# MIMXRT1042 register map
Vendor: nxp.com; File version: 1.0
CPU: CM7 r0p1, little endian, MPU, FPU, VTOR, 4 interrupt priority bits
Registers are 32-bit, read-write, reset 0x0 unless marked. A register's access mark holds for its fields unless they carry their own. Offsets are from the block's base; [hi:lo] are bit positions; {n}, {i} and the like mark numbered series.

## USDHC1 — uSDHC
Base 0x402C0000
Same registers: USDHC2 0x402C4000
0x00 DS_ADDR — DMA System Address
  [31:0] DS_ADDR — System address
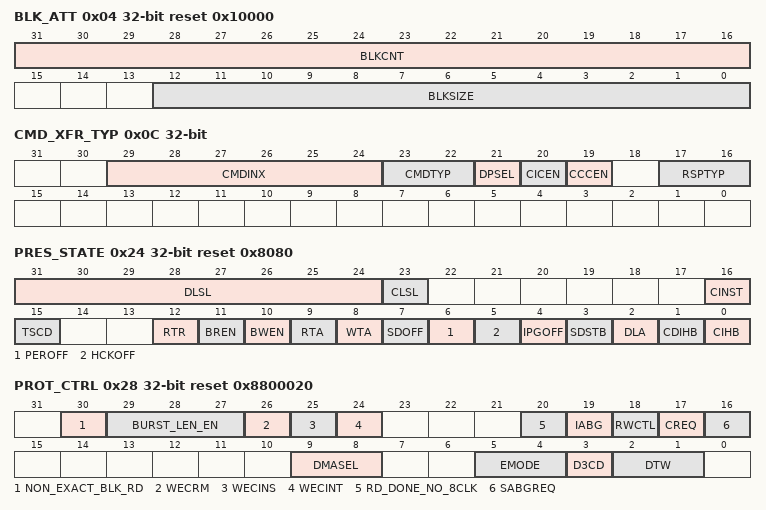
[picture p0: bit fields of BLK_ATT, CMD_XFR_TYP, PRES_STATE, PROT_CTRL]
0x04 BLK_ATT reset 0x10000 — Block Attributes
  [31:16] BLKCNT — Blocks count for current transfer
    0=BLKCNT_d (Stop count); 1=BLKCNT_c (1 block); 2=BLKCNT_b (2 blocks); 0xFFFF=BLKCNT_a (65535 blocks)
  [12:0] BLKSIZE — Transfer block size
    0=BLK_ATT_i (No data transfer); 1=BLK_ATT_h (1 byte); 2=BLK_ATT_g (2 bytes); 3=BLK_ATT_f (3 bytes); 4=BLK_ATT_e (4 bytes); 0x1FF=BLK_ATT_d (511 bytes); 0x200=BLK_ATT_c (512 bytes); 0x800=BLK_ATT_b (2048 bytes); 0x1000=BLK_ATT_a (4096 bytes)
0x08 CMD_ARG — Command Argument
  [31:0] CMDARG — Command argument
0x0C CMD_XFR_TYP — Command Transfer Type
  [29:24] CMDINX — Command index
  [23:22] CMDTYP — Command type
    0=CMDTYP_d (Normal other commands); 1=CMDTYP_c (Suspend CMD52 for writing bus suspend in CCCR); 2=CMDTYP_b (Resume CMD52 for writing function select in CCCR); 3=CMDTYP_a (Abort CMD12, CMD52 for writing I/O Abort in CCCR)
  [21] DPSEL — Data present select
    0=DPSEL_b (No data present); 1=DPSEL_a (Data present)
  [20] CICEN — Command index check enable
    0=CICEN_b (Disable command index check); 1=CICEN_a (Enables command index check)
  [19] CCCEN — Command CRC check enable
    0=CCCEN_b (Disables command CRC check); 1=CCCEN_a (Enables command CRC check)
  [17:16] RSPTYP — Response type select
    0=RSPTYP_a (No response); 1=RSPTYP_b (Response length 136); 2=RSPTYP_c (Response length 48); 3=RSPTYP_d (Response length 48, check busy after response)
{0x10+4i} CMD_RSP{i} ro (i=0..3) — Command Response{i}
  [31:0] CMDRSP{i} — Command response {i}
0x20 DATA_BUFF_ACC_PORT — Data Buffer Access Port
  [31:0] DATCONT — Data content
0x24 PRES_STATE ro reset 0x8080 (reset mask 0x7EFFFF) — Present State
  [31:24] DLSL — DATA[7:0] line signal level
    {v}=DATA{v} (Data {v} line signal level) (v=0..7)
  [23] CLSL — CMD line signal level
  [16] CINST — Card inserted
    0=CINST_a (Power on reset or no card); 1=CINST_B (Card inserted)
  [15] TSCD — Tap select change done
    0=TSCD_B (Delay cell select change is not finished.); 1=TSCD_A (Delay cell select change is finished.)
  [12] RTR — Re-Tuning Request (only for SD3.0 SDR104 mode,and eMMC HS200 mode)
    0=RTR_B (Fixed or well tuned sampling clock); 1=RTR_A (Sampling clock needs re-tuning)
  [11] BREN — Buffer read enable
    0=BREN_B (Read disable); 1=BREN_A (Read enable)
  [10] BWEN — Buffer write enable
    0=BWEN_b (Write disable); 1=BWEN_A (Write enable)
  [9] RTA — Read transfer active
    0=RTA_B (No valid data); 1=RTA_A (Transferring data)
  [8] WTA — Write transfer active
    0=WTA_B (No valid data); 1=WTA_A (Transferring data)
  [7] SDOFF — SD clock gated off internally
    0=SDOFF_D (SD clock is active.); 1=SDOFF_C (SD clock is gated off.)
  [6] PEROFF — IPG_PERCLK gated off internally
    0=PEROFF_b (IPG_PERCLK is active.); 1=PEROFF_A (IPG_PERCLK is gated off.)
  [5] HCKOFF — HCLK gated off internally
    0=HCKOFF_B (HCLK is active.); 1=HCKOFF_A (HCLK is gated off.)
  [4] IPGOFF — Peripheral clock gated off internally
    0=IPGOFF_b (Peripheral clock is active.); 1=IPGOFF_A (Peripheral clock is gated off.)
  [3] SDSTB — SD clock stable
    0=SDSTB_b (Clock is changing frequency and not stable.); 1=SDSTB_A (Clock is stable.)
  [2] DLA — Data line active
    0=DLA_A (DATA line inactive); 1=DLA_b (DATA line active)
  [1] CDIHB — Command Inhibit Data (DATA)
    0=CDIHB_b (Can issue command that uses the DATA line); 1=CDIHB_A (Cannot issue command that uses the DATA line)
  [0] CIHB — Command inhibit (CMD)
    0=CIHB_a (Can issue command using only CMD line); 1=CIHB_b (Cannot issue command)
0x28 PROT_CTRL reset 0x8800020 — Protocol Control
  [30] NON_EXACT_BLK_RD — Non-exact block read
    0=EXACT_B (The block read is exact block read. Host driver does not need to issue abort command to terminate this multi-block read.); 1=EXACT_A (The block read is non-exact block read. Host driver needs to issue abort command to terminate this multi-block read.)
  [29:27] BURST_LEN_EN — BURST length enable for INCR, INCR4 / INCR8 / INCR16, INCR4-WRAP / INCR8-WRAP / INCR16-WRAP
    0bxx1=BURST_A (Burst length is enabled for INCR.)
  [26] WECRM — Wakeup event enable on SD card removal
    0=WECRM_B (Disables wakeup event enable on SD card removal); 1=WECRM_A (Enables wakeup event enable on SD card removal)
  [25] WECINS — Wakeup event enable on SD card insertion
    0=WECINS_b (Disable wakeup event enable on SD card insertion); 1=WECINS_A (Enable wakeup event enable on SD card insertion)
  [24] WECINT — Wakeup event enable on card interrupt
    0=WECINT_A (Disables wakeup event enable on card interrupt); 1=WECINT_b (Enables wakeup event enable on card interrupt)
  [20] RD_DONE_NO_8CLK — Read performed number 8 clock
  [19] IABG — Interrupt at block gap
    0=IABG_b (Disables interrupt at block gap); 1=IABG_A (Enables interrupt at block gap)
  [18] RWCTL — Read wait control
    0=RWCTL_b (Disables read wait control and stop SD clock at block gap when SABGREQ field is set); 1=RWCTL_A (Enables read wait control and assert read wait without stopping SD clock at block gap when SABGREQ field is set)
  [17] CREQ — Continue request
    0=CREQ_B (No effect); 1=CREQ_A (Restart)
  [16] SABGREQ — Stop at block gap request
    0=SABGREQ_b (Transfer); 1=SABGREQ_A (Stop)
  [9:8] DMASEL — DMA select
    0=DMASEL_A (No DMA or simple DMA is selected.); 1=DMASEL_b (ADMA1 is selected.); 2=DMASEL_C (ADMA2 is selected.)
  [5:4] EMODE — Endian mode
    0=EMODE_A (Big endian mode); 1=EMODE_B (Half word big endian mode); 2=EMODE_C (Little endian mode)
  [3] D3CD — DATA3 as card detection pin
    0=D3CD_B (DATA3 does not monitor card insertion); 1=D3CD_A (DATA3 as card detection pin)
  [2:1] DTW — Data transfer width
    0=DTW_C (1-bit mode); 1=DTW_B (4-bit mode); 2=DTW_A (8-bit mode)
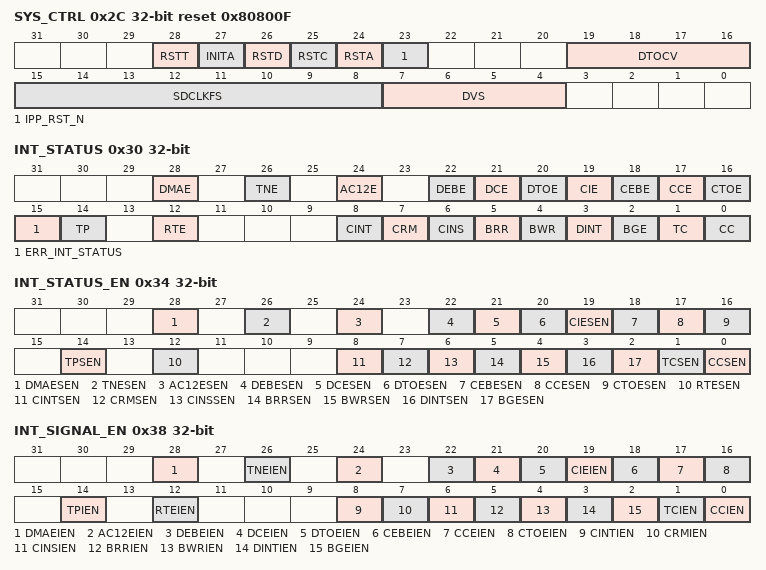
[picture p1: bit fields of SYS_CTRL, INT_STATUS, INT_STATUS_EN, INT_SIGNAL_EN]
0x2C SYS_CTRL reset 0x80800F — System Control
  [28] RSTT — Reset tuning
  [27] INITA — Initialization active
  [26] RSTD — Software reset for data line
    0=RSTD_B (No reset); 1=RSTD_A (Reset)
  [25] RSTC — Software reset for CMD line
    0=RSTC_B (No reset); 1=RSTC_A (Reset)
  [24] RSTA — Software reset for all
    0=RSTA_B (No reset); 1=RSTA_A (Reset)
  [23] IPP_RST_N — Hardware reset
  [19:16] DTOCV — Data timeout counter value
    0=DTOCV_Q (SDCLK x 2 14); 1=DTOCV_P (SDCLK x 2 15); 2=DTOCV_O (SDCLK x 2 16); 3=DTOCV_N (SDCLK x 2 17); 4=DTOCV_M (SDCLK x 2 18); 5=DTOCV_L (SDCLK x 2 19); 6=DTOCV_K (SDCLK x 2 20); 7=DTOCV_J (SDCLK x 2 21); 8=DTOCV_I (SDCLK x 2 22); 9=DTOCV_H (SDCLK x 2 23); 10=DTOCV_G (SDCLK x 2 24); 11=DTOCV_F (SDCLK x 2 25); 12=DTOCV_E (SDCLK x 2 26); 13=DTOCV_D (SDCLK x 2 27); 14=DTOCV_C (SDCLK x 2 28); 15=DTOCV_A (SDCLK x 2 29)
  [15:8] SDCLKFS — SDCLK frequency select
  [7:4] DVS — Divisor
    0=DVS_A (Divide-by-1); 1=DVS_B (Divide-by-2); 14=DVS_C (Divide-by-15); 15=DVS_D (Divide-by-16)
0x30 INT_STATUS — Interrupt Status
  [28] DMAE write-1-clears — DMA error
    0=DMAE_A (No error); 1=DMAE_b (Error)
  [26] TNE write-1-clears — Tuning error: (only for SD3.0 SDR104 mode and eMMC HS200 mode)
  [24] AC12E write-1-clears — Auto CMD12 error
    0=AC12E_A (No error); 1=AC12E_b (Error)
  [22] DEBE write-1-clears — Data end bit error
    0=DEBE_A (No error); 1=DEBE_b (Error)
  [21] DCE write-1-clears — Data CRC error
    0=DCE_A (No error); 1=DCE_b (Error)
  [20] DTOE write-1-clears — Data timeout error
    0=DTOE_A (No error); 1=DTOE_b (Time out)
  [19] CIE write-1-clears — Command index error
    0=CIE_A (No error); 1=CIE_b (Error)
  [18] CEBE write-1-clears — Command end bit error
    0=CEBE_A (No error); 1=CEBE_b (End bit error generated)
  [17] CCE write-1-clears — Command CRC error
    0=CCE_A (No error); 1=CCE_b (CRC error generated)
  [16] CTOE write-1-clears — Command timeout error
    0=CTOE_A (No error); 1=CTOE_b (Time out)
  [15] ERR_INT_STATUS ro — Error Interrupt Status
  [14] TP write-1-clears — Tuning pass:(only for SD3.0 SDR104 mode and eMMC HS200 mode)
  [12] RTE write-1-clears — Re-tuning event: (only for SD3.0 SDR104 mode and eMMC HS200 mode)
    0=RTE_A (Re-tuning is not required.); 1=RTE_b (Re-tuning should be performed.)
  [8] CINT write-1-clears — Card interrupt
    0=CINT_A (No card interrupt); 1=CINT_b (Generate card interrupt)
  [7] CRM write-1-clears — Card removal
    0=CRM_A (Card state unstable or inserted); 1=CRM_b (Card removed)
  [6] CINS write-1-clears — Card insertion
    0=BWR_b (Card state unstable or removed); 1=BWR_A (Card inserted)
  [5] BRR write-1-clears — Buffer read ready
    0=BRR_B (Not ready to read buffer); 1=BRR_A (Ready to read buffer)
  [4] BWR write-1-clears — Buffer write ready
    0=BWR_B (Not ready to write buffer); 1=BWR_A (Ready to write buffer)
  [3] DINT write-1-clears — DMA interrupt
    0=DINT_B (No DMA interrupt); 1=DINT_A (DMA interrupt is generated.)
  [2] BGE write-1-clears — Block gap event
    0=BGE_B (No block gap event); 1=BGE_A (Transaction stopped at block gap)
  [1] TC write-1-clears — Transfer complete
    0=TC_B (Transfer does not complete); 1=TC_A (Transfer complete)
  [0] CC write-1-clears — Command complete
    0=CC_B (Command not complete); 1=CC_A (Command complete)
0x34 INT_STATUS_EN — Interrupt Status Enable
  [28] DMAESEN — DMA error status enable
    0=DMASEN_b (Masked); 1=DMASEN_a (Enabled)
  [26] TNESEN — Tuning error status enable
    0=TNESEN_A (Masked); 1=TNESEN_b (Enabled)
  [24] AC12ESEN — Auto CMD12 error status enable
    0=AC12ESEN_A (Masked); 1=AC12ESEN_b (Enabled)
  [22] DEBESEN — Data end bit error status enable
    0=DBESEN_A (Masked); 1=DBESEN_b (Enabled)
  [21] DCESEN — Data CRC error status enable
    0=DCESEN_A (Masked); 1=DCESEN_b (Enabled)
  [20] DTOESEN — Data timeout error status enable
    0=DTOESEN_A (Masked); 1=DTOESEN_b (Enabled)
  [19] CIESEN — Command index error status enable
    0=CIESEN_A (Masked); 1=CIESEN_b (Enabled)
  [18] CEBESEN — Command end bit error status enable
    0=CEBESEN_A (Masked); 1=CEBESEN_b (Enabled)
  [17] CCESEN — Command CRC error status enable
    0=CCESEN_A (Masked); 1=CCESEN_b (Enabled)
  [16] CTOESEN — Command timeout error status enable
    0=CTOSEN_A (Masked); 1=CTOSEN_b (Enabled)
  [14] TPSEN — Tuning pass status enable
    0=TPSEN_A (Masked); 1=TPSEN_b (Enabled)
  [12] RTESEN — Re-tuning event status enable
    0=RTESEN_A (Masked); 1=RTESEN_b (Enabled)
  [8] CINTSEN — Card interrupt status enable
    0=CINTSEN_A (Masked); 1=CINTSEN_b (Enabled)
  [7] CRMSEN — Card removal status enable
    0=CRMSEN_A (Masked); 1=CRMSEN_b (Enabled)
  [6] CINSSEN — Card insertion status enable
    0=CINSEN_A (Masked); 1=CINSEN_b (Enabled)
  [5] BRRSEN — Buffer read ready status enable
    0=BRRSEN_A (Masked); 1=BRREN_b (Enabled)
  [4] BWRSEN — Buffer write ready status enable
    0=BWRSEN_A (Masked); 1=BWRSEN_b (Enabled)
  [3] DINTSEN — DMA interrupt status enable
    0=DINTSEN_A (Masked); 1=DINTSEN_b (Enabled)
  [2] BGESEN — Block gap event status enable
    0=BGESEN_A (Masked); 1=BGESEN_b (Enabled)
  [1] TCSEN — Transfer complete status enable
    0=TCSEN_b (Masked); 1=TCSEN_A (Enabled)
  [0] CCSEN — Command complete status enable
    0=CCSEN_a (Masked); 1=CCSEN_b (Enabled)
0x38 INT_SIGNAL_EN — Interrupt Signal Enable
  [28] DMAEIEN — DMA error interrupt enable
    0=DMAEIEN_B (Masked); 1=DMAEIEN_a (Enable)
  [26] TNEIEN — Tuning error interrupt enable
    0=TNEIEN_B (Masked); 1=TNEIEN_a (Enabled)
  [24] AC12EIEN — Auto CMD12 error interrupt enable
    0=AC12EIEN_b (Masked); 1=AC12EIEN_a (Enabled)
  [22] DEBEIEN — Data end bit error interrupt enable
    0=DEBEIEN_B (Masked); 1=DEBEIEN_a (Enabled)
  [21] DCEIEN — Data CRC error interrupt enable
    0=DCEIEN_B (Masked); 1=DCEIEN_a (Enabled)
  [20] DTOEIEN — Data timeout error interrupt enable
    0=DTOEIEN_B (Masked); 1=DTOEIEN_a (Enabled)
  [19] CIEIEN — Command index error interrupt enable
    0=CIEIEN_B (Masked); 1=CIEIEN_a (Enabled)
  [18] CEBEIEN — Command end bit error interrupt enable
    0=CEBEIEN_b (Masked); 1=CEBEIEN_a (Enabled)
  [17] CCEIEN — Command CRC error interrupt enable
    0=CCEIEN_B (Masked); 1=CCEIEN_a (Enabled)
  [16] CTOEIEN — Command timeout error interrupt enable
    0=CTOEIEN_b (Masked); 1=CTOEIEN_a (Enabled)
  [14] TPIEN — Tuning Pass interrupt enable
    0=TPIEN_R (Masked); 1=TPIEN_Q (Enabled)
  [12] RTEIEN — Re-tuning event interrupt enable
    0=RTEIEN_O (Masked); 1=RTEIEN_N (Enabled)
  [8] CINTIEN — Card interrupt enable
    0=CINTIEN_b (Masked); 1=CINTIEN_a (Enabled)
  [7] CRMIEN — Card removal interrupt enable
    0=CRMIEN_a (Masked); 1=CRMIEN_b (Enabled)
  [6] CINSIEN — Card insertion interrupt enable
    0=CINSIEN_a (Masked); 1=CINSIEN_b (Enabled)
  [5] BRRIEN — Buffer read ready interrupt enable
    0=BRRIEN_b (Masked); 1=BRRIEN_a (Enabled)
  [4] BWRIEN — Buffer write ready interrupt enable
    0=BWRIEN_a (Masked); 1=BWRIEN_b (Enabled)
  [3] DINTIEN — DMA interrupt enable
    0=DINTIEN_b (Masked); 1=DINTIEN_a (Enabled)
  [2] BGEIEN — Block gap event interrupt enable
    0=BGIEN_a (Masked); 1=BGIEN_b (Enabled)
  [1] TCIEN — Transfer complete interrupt enable
    0=TCIEN_a (Masked); 1=TCIEN_b (Enabled)
  [0] CCIEN — Command complete interrupt enable
    0=CCIEN_a (Masked); 1=CCIEN_b (Enabled)
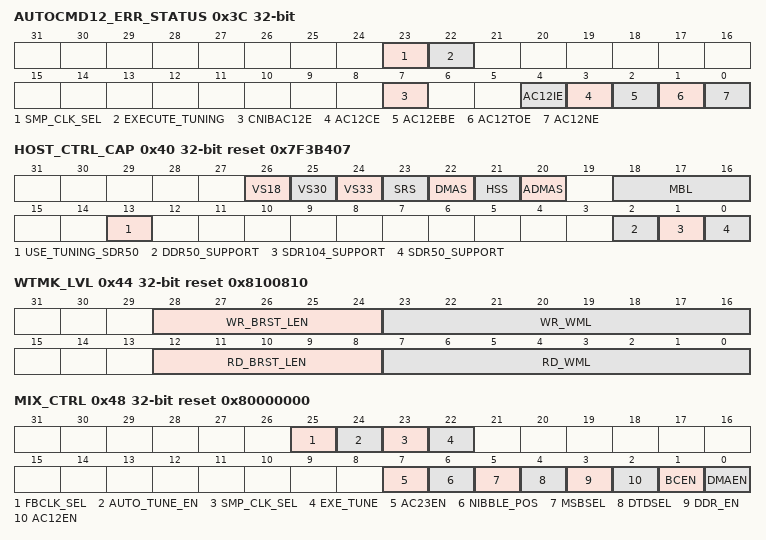
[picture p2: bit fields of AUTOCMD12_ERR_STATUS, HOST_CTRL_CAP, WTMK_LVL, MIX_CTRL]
0x3C AUTOCMD12_ERR_STATUS — Auto CMD12 Error Status
  [23] SMP_CLK_SEL — Sample clock select
    0=SMP_CLK_B (Fixed clock is used to sample data); 1=SMP_CLK_a (Tuned clock is used to sample data)
  [22] EXECUTE_TUNING
    0=EX_TUN_B (Tuning procedure is aborted); 1=ex_tun_a (Start tuning procedure)
  [7] CNIBAC12E ro — Command not issued by Auto CMD12 error
    0=CNIBAC12E_B (No error); 1=CNIBAC12E_a (Not issued)
  [4] AC12IE ro — Auto CMD12 / 23 index error
    0=AC12IE_B (No error); 1=AC12IE_a (Error, the CMD index in response is not CMD12/23)
  [3] AC12CE ro — Auto CMD12 / 23 CRC error
    0=AC12CE_B (No CRC error); 1=AC12CE_a (CRC error met in Auto CMD12/23 response)
  [2] AC12EBE ro — Auto CMD12 / 23 end bit error
    0=AC12EBE_B (No error); 1=AC12EBE_a (End bit error generated)
  [1] AC12TOE ro — Auto CMD12 / 23 timeout error
    0=AC12TOE_B (No error); 1=AC12TOE_a (Time out)
  [0] AC12NE ro — Auto CMD12 not executed
    0=AC12NE_B (Executed); 1=AC12NE_a (Not executed)
0x40 HOST_CTRL_CAP reset 0x7F3B407 — Host Controller Capabilities
  [26] VS18 ro — Voltage support 1.8 V
    0=VS18_B (1.8 V not supported); 1=VS18_a (1.8 V supported)
  [25] VS30 ro — Voltage support 3.0 V
    0=VS30_b (3.0 V not supported); 1=VS30_a (3.0 V supported)
  [24] VS33 ro — Voltage support 3.3 V
    0=VS33_b (3.3 V not supported); 1=VS33_a (3.3 V supported)
  [23] SRS ro — Suspend / resume support
    0=SRS_B (Not supported); 1=SRS_a (Supported)
  [22] DMAS ro — DMA support
    0=DMAS_B (DMA not supported); 1=DMAS_a (DMA supported)
  [21] HSS ro — High speed support
    0=HSS_B (High speed not supported); 1=HSS_a (High speed supported)
  [20] ADMAS ro — ADMA support
    0=ADMAS_B (Advanced DMA not supported); 1=ADMAS_a (Advanced DMA supported)
  [18:16] MBL ro — Max block length
    0=MBL_a (512 bytes); 1=MBL_B (1024 bytes); 2=MBL_C (2048 bytes); 3=MBL_D (4096 bytes)
  [13] USE_TUNING_SDR50 — Use Tuning for SDR50
    0=USE_TUNING_b (SDR50 does not support tuning); 1=USE_TUNING_a (SDR50 supports tuning)
  [2] DDR50_SUPPORT ro
  [1] SDR104_SUPPORT ro
  [0] SDR50_SUPPORT ro
0x44 WTMK_LVL reset 0x8100810 — Watermark Level
  [28:24] WR_BRST_LEN — Write burst length due to system restriction, the actual burst length might not exceed 16
  [23:16] WR_WML — Write watermark level
  [12:8] RD_BRST_LEN — Read burst length due to system restriction, the actual burst length might not exceed 16
  [7:0] RD_WML — Read watermark level
0x48 MIX_CTRL reset 0x80000000 — Mixer Control
  [25] FBCLK_SEL — Feedback clock source selection (Only used for SD3.0, SDR104 mode and eMMC HS200 mode)
    0=FBCLK_B (Feedback clock comes from the loopback CLK); 1=FBCLK_a (Feedback clock comes from the ipp_card_clk_out)
  [24] AUTO_TUNE_EN — Auto tuning enable (Only used for SD3.0, SDR104 mode and and eMMC HS200 mode)
    0=AUTOTUNE_B (Disable auto tuning); 1=AUTO_TUNE_a (Enable auto tuning)
  [23] SMP_CLK_SEL — Clock selection
    0=SMPSEL_B (Fixed clock is used to sample data / cmd); 1=SMPSEL_a (Tuned clock is used to sample data / cmd)
  [22] EXE_TUNE — Execute tuning: (Only used for SD3.0, SDR104 mode and eMMC HS200 mode)
    0=EXE_TUNE_D (Not tuned or tuning completed); 1=EXE_TUNE_C (Execute tuning)
  [7] AC23EN — Auto CMD23 enable
  [6] NIBBLE_POS — Nibble position indication
  [5] MSBSEL — Multi / Single block select
    0=MSBSEL_B (Single block); 1=MSBSEL_a (Multiple blocks)
  [4] DTDSEL — Data transfer direction select
    0=DTDSEL_B (Write (Host to card)); 1=DTDSEL_a (Read (Card to host))
  [3] DDR_EN — Dual data rate mode selection
  [2] AC12EN — Auto CMD12 enable
    0=AC12EN_B (Disable); 1=AC12EN_a (Enable)
  [1] BCEN — Block count enable
    0=BCEN_B (Disable); 1=BCEN_a (Enable)
  [0] DMAEN — DMA enable
    0=DMAIN_B (Disable); 1=DMAIN_a (Enable)
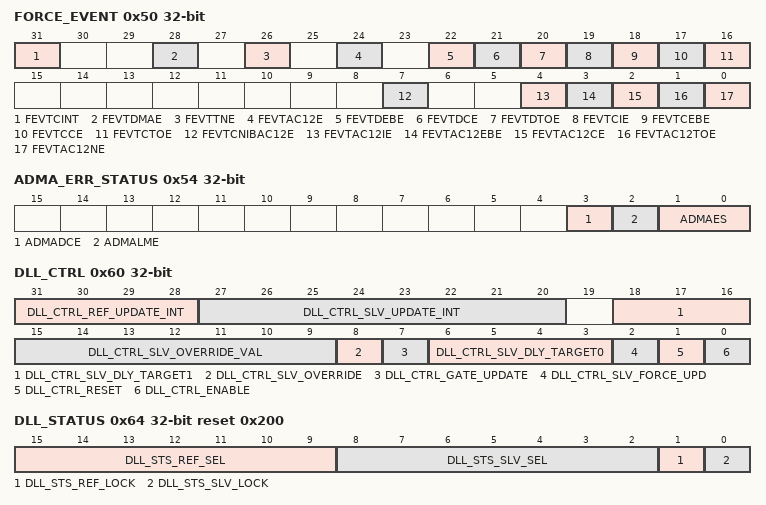
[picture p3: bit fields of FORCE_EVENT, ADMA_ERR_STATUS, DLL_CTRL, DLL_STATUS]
0x50 FORCE_EVENT
  [31] FEVTCINT — Force event card interrupt
  [28] FEVTDMAE — Force event DMA error
  [26] FEVTTNE — Force tuning error
  [24] FEVTAC12E — Force event Auto Command 12 error
  [22] FEVTDEBE — Force event data end bit error
  [21] FEVTDCE — Force event data CRC error
  [20] FEVTDTOE — Force event data time out error
  [19] FEVTCIE — Force event command index error
  [18] FEVTCEBE — Force event command end bit error
  [17] FEVTCCE — Force event command CRC error
  [16] FEVTCTOE — Force event command time out error
  [7] FEVTCNIBAC12E — Force event command not executed by Auto Command 12 error
  [4] FEVTAC12IE — Force event Auto Command 12 index error
  [3] FEVTAC12EBE — Force event Auto Command 12 end bit error
  [2] FEVTAC12CE — Force event auto command 12 CRC error
  [1] FEVTAC12TOE — Force event auto command 12 time out error
  [0] FEVTAC12NE — Force event auto command 12 not executed
0x54 ADMA_ERR_STATUS ro — ADMA Error Status
  [3] ADMADCE — ADMA descriptor error
    0=ADMADCE_B (No error); 1=ADMADCE_a (Error)
  [2] ADMALME — ADMA length mismatch error
    0=ADMAES_B (No error); 1=ADMAES_a (Error)
  [1:0] ADMAES — ADMA error state (when ADMA error is occurred)
0x58 ADMA_SYS_ADDR — ADMA System Address
  [31:2] ADS_ADDR — ADMA system address
0x60 DLL_CTRL — DLL (Delay Line) Control
  [31:28] DLL_CTRL_REF_UPDATE_INT — DLL control loop update interval
  [27:20] DLL_CTRL_SLV_UPDATE_INT — Slave delay line update interval
  [18:16] DLL_CTRL_SLV_DLY_TARGET1 — DLL slave delay target1
  [15:9] DLL_CTRL_SLV_OVERRIDE_VAL — DLL slave override val
  [8] DLL_CTRL_SLV_OVERRIDE — DLL slave override
  [7] DLL_CTRL_GATE_UPDATE — DLL gate update
  [6:3] DLL_CTRL_SLV_DLY_TARGET0 — DLL slave delay target0
  [2] DLL_CTRL_SLV_FORCE_UPD — DLL slave delay line
  [1] DLL_CTRL_RESET — DLL reset
  [0] DLL_CTRL_ENABLE — DLL and delay chain
0x64 DLL_STATUS ro reset 0x200
  [15:9] DLL_STS_REF_SEL — Reference delay line select taps
  [8:2] DLL_STS_SLV_SEL — Slave delay line select status
  [1] DLL_STS_REF_LOCK — Reference DLL lock status
  [0] DLL_STS_SLV_LOCK — Slave delay-line lock status
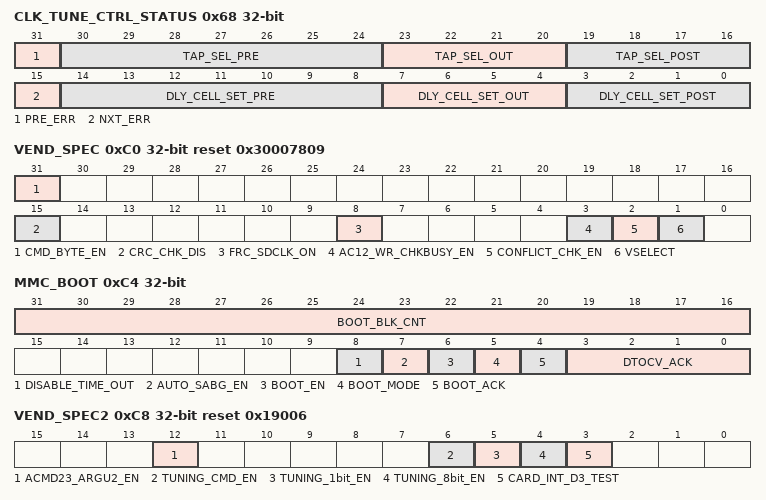
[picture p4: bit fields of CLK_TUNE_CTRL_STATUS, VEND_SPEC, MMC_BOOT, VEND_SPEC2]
0x68 CLK_TUNE_CTRL_STATUS — CLK Tuning Control and Status
  [31] PRE_ERR ro — PRE error
  [30:24] TAP_SEL_PRE ro
  [23:20] TAP_SEL_OUT ro — Delay cells added on the feedback clock between CLK_PRE and CLK_OUT
  [19:16] TAP_SEL_POST ro — Delay cells added on the feedback clock between CLK_OUT and CLK_POST
  [15] NXT_ERR ro — NXT error
  [14:8] DLY_CELL_SET_PRE — delay cells on the feedback clock between the feedback clock and CLK_PRE
  [7:4] DLY_CELL_SET_OUT — Delay cells on the feedback clock between CLK_PRE and CLK_OUT
  [3:0] DLY_CELL_SET_POST — Delay cells on the feedback clock between CLK_OUT and CLK_POST
0xC0 VEND_SPEC reset 0x30007809 — Vendor Specific Register
  [31] CMD_BYTE_EN — Byte access
    0=CMD_BYTE_EN_a (Disable); 1=CMD_BYTE_EN_b (Enable)
  [15] CRC_CHK_DIS — CRC Check Disable
    0=CRC_CHK_DIS_a (Check CRC16 for every read data packet and check CRC fields for every write data packet); 1=CRC_CHK_DIS_B (Ignore CRC16 check for every read data packet and ignore CRC fields check for every write data packet)
  [8] FRC_SDCLK_ON — Force CLK
    0=FRC_SDCLK_ON_a (CLK active or inactive is fully controlled by the hardware.); 1=FRC_SDCLK_ON_B (Force CLK active)
  [3] AC12_WR_CHKBUSY_EN — Check busy enable
    0=AC12_WR_CHKBUSY_EN_a (Do not check busy after auto CMD12 for write data packet); 1=AC12_WR_CHKBUSY_EN_b (Check busy after auto CMD12 for write data packet)
  [2] CONFLICT_CHK_EN — Conflict check enable
    0=CONFLICT_CHK_EN_a (Conflict check disable); 1=CONFLICT_CHK_EN_b (Conflict check enable)
  [1] VSELECT — Voltage selection
    0=VSELECT_B (Change the voltage to high voltage range, around 3.0 V); 1=VSELECT_a (Change the voltage to low voltage range, around 1.8 V)
0xC4 MMC_BOOT — eMMC Boot
  [31:16] BOOT_BLK_CNT — Stop At Block Gap value of automatic mode
  [8] DISABLE_TIME_OUT — Time out
    0=disable_timeout_a (Enable time out); 1=disable_timeout_b
  [7] AUTO_SABG_EN — Auto stop at block gap
  [6] BOOT_EN — Boot enable
    0=BOOT_en_a (Fast boot disable); 1=BOOT_en_b (Fast boot enable)
  [5] BOOT_MODE
    0=BOOT_mode_a (Normal boot); 1=BOOT_mode_b (Alternative boot)
  [4] BOOT_ACK
    0=BOOT_ACK_a (No ack); 1=BOOT_ACK_b (Ack)
  [3:0] DTOCV_ACK — Boot ACK time out
    0=DTOCV_ACK_a (SDCLK x 2^14); 1=DTOCV_ACK_b (SDCLK x 2^15); 2=DTOCV_ACK_c (SDCLK x 2^16); 3=DTOCV_ACK_d (SDCLK x 2^17); 4=DTOCV_ACK_e (SDCLK x 2^18); 5=DTOCV_ACK_f (SDCLK x 2^19); 6=DTOCV_ACK_g (SDCLK x 2^20); 7=DTOCV_ACK_h (SDCLK x 2^21); 14=DTOCV_ACK_i (SDCLK x 2^28); 15=DTOCV_ACK_j (SDCLK x 2^29)
0xC8 VEND_SPEC2 reset 0x19006 — Vendor Specific 2 Register
  [12] ACMD23_ARGU2_EN — Argument2 register enable for ACMD23
    0=ACMD23_ARGU2_EN_B (Disable); 1=ACMD23_ARGU2_EN_a (Argument2 register enable for ACMD23 sharing with SDMA system address register. Default is enabled.)
  [6] TUNING_CMD_EN — Tuning command enable
    0=TUNING_CMD_EN_a (Auto tuning circuit does not check the CMD line.); 1=TUNING_CMD_EN_B (Auto tuning circuit checks the CMD line.)
  [5] TUNING_1bit_EN — Tuning 1bit enable
  [4] TUNING_8bit_EN — Tuning 8bit enable
  [3] CARD_INT_D3_TEST — Card interrupt detection test
    0=CARD_INT_D3_a (Check the card interrupt only when DATA3 is high.); 1=CARD_INT_D3_B (Check the card interrupt by ignoring the status of DATA3.)
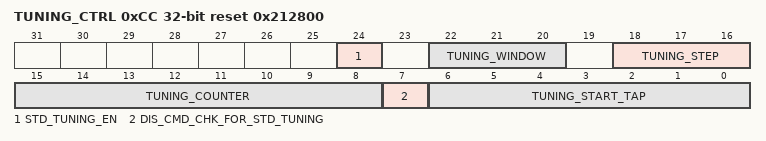
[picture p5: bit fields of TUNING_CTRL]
0xCC TUNING_CTRL reset 0x212800 — Tuning Control
  [24] STD_TUNING_EN — Standard tuning circuit and procedure enable
  [22:20] TUNING_WINDOW — Data window
  [18:16] TUNING_STEP
  [15:8] TUNING_COUNTER
  [7] DIS_CMD_CHK_FOR_STD_TUNING — Disable command check for standard tuning
  [6:0] TUNING_START_TAP — Tuning start
